# C7XV_RSWS_BS_LIMITER11_REGS register map
Vendor: Texas Instruments
Peripheral module from a debugger description file (folder J722S).
Registers are 32-bit, read-only, reset 0x0 unless marked. A register's access mark holds for its fields unless they carry their own. Offsets are as the file gives them; lines under a group give offsets from that group; [hi:lo] are bit positions; {n}, {i} and the like mark numbered series; 'fields as' and 'values as' point back to an identical list; <NAME> marks a mode.

## C7XV_RSWS_BS_LIMITER11_REGS
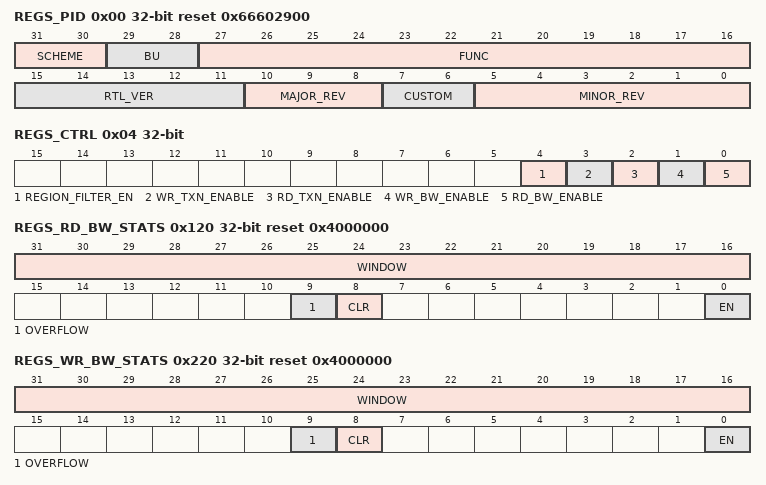
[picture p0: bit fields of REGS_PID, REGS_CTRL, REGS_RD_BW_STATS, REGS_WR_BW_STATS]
0x00 REGS_PID reset 0x66602900 — This is the standard TI peripheral ID register that exists at address 0 in the peripheral space
  [31:30] SCHEME — PID scheme
  [29:28] BU — PID bu identifier
  [27:16] FUNC — PID function identifier
  [15:11] RTL_VER — PID RTL version number
  [10:8] MAJOR_REV — PID Major revision number
  [7:6] CUSTOM — PID custom
  [5:0] MINOR_REV — PID Minor revision number
0x04 REGS_CTRL rw — This register controls the overall behavior of the rate limiter module
  [4] REGION_FILTER_EN — Enable the region filter, which will only apply the bandwith and transaction limits to the configured address regions
  [3] WR_TXN_ENABLE — Enable limiting maximum outstanding write transactions
  [2] RD_TXN_ENABLE — Enable limiting maximum outstanding read transactions
  [1] WR_BW_ENABLE — Enable write bandwidth limiting
  [0] RD_BW_ENABLE — Enable read bandwidth limiting
0x100 REGS_RD_BW_CIR rw — Read Bandwidth Committed Information Rate
  [31:0] CIR — Committed Information Rate
0x104 REGS_RD_BW_PIR rw — Read Bandwidth Peak Information Rate
  [31:0] PIR — Peak Information Rate
0x108 REGS_RD_BW_BURST_OFFSET rw — Read Bandwidth Burst Offset
  [15:0] OFFSET — Burst Offset - the number of bytes before the Committed Information Rate is applied at startup or after a period of inactivity. Peak Information Rate will still apply
0x10C REGS_RD_BW_INFO — Read Bandwidth State machine information. Primarly for verification purposes
  [1:0] COLOR — Read Bandwidth three-color marker output from rategen submodule
0x120 REGS_RD_BW_STATS access per field reset 0x4000000 — Read Bandwidth Statistics Control Register
  [31:16] WINDOW rw — Statistics window size. This cannot be set to 0. If 16'd0 is written, it will be set to the reset value of 16'd1024
  [9] OVERFLOW ro — Statistics overflow error
  [8] CLR wo — Clear statistics data. Resets statistics counters at 0
  [0] EN rw — Enable read bandwidth statistics
0x124 REGS_RD_BW_STATS_THRSHLD rw — A statistics threshold separate from the CIR and PIR
  [31:0] THRESHOLD — Read bandwidth stats threshold in bytes. Note that this is total bytes, unlike CIR and PIR. CIR and PIR are based on a rolling window, and the statistics threshold is based on a fixed window. This will still take into account DDR bytes used, so can be compared to CIR and PIR directly if the bandwidths are converted via the equations for CIR and PIR. The threshold bandwidth is programmed here as bytes per window
0x128 REGS_RD_BW_WINDOWS_CNT — Read Bandwidth Statistics - Window Count
  [31:0] VAL — Read bandwidth window count - the number of windows elapsed since statistics collection began
0x12C REGS_RD_BW_CIR_CNT — Read Bandwidth Statistics - CIR Count
  [31:0] VAL — The total number of statistics windows in which Read Commit Information Rate occurred. Note that if PIR is set to a lower value than CIR or if the burst offset feature is used, this will also count times that PIR is reached.
0x130 REGS_RD_BW_PIR_CNT — Read Bandwidth Statistics - PIR Count
  [31:0] VAL — The total number of statistics windows in which Read Peak Information Rate occurred
0x134 REGS_RD_BW_THRSHLD_CNT — Read Bandwidth Statistics - Threshold Count
  [31:0] VAL — The total number of statistics windows in which Read bytes transferred exceeded the statistics threshold
0x138 REGS_RD_BYTES_MAX — The maximum number of bytes seen in a single statitsics window. This can be compared with the window size to calculate the maximum bandwidth seen
  [31:0] VAL — Max number of bytes in a single window. This number accounts for DDR bandwidth consumed, not simply the accumulation of the packet bytecnt values across a window. The max bandwidth calculation is the total bytes value in this MMR divided by the windows size in RD_BW_STATS.window and multiplied with the interface frequency: RD_BYTES_MAX * FREQ / RD_BW_STATS.window
0x200 REGS_WR_BW_CIR rw — Write Bandwidth Committed Information Rate
  [31:0] CIR — Committed Information Rate
0x204 REGS_WR_BW_PIR rw — Write Bandwidth Peak Information Rate
  [31:0] PIR — Peak Information Rate
0x208 REGS_WR_BW_BURST_OFFSET rw — Write Bandwidth Burst Offset
  fields as REGS_RD_BW_BURST_OFFSET
0x20C REGS_WR_BW_INFO — Write Bandwidth State machine information. Primarly for verification purposes
  [1:0] COLOR — Write Bandwidth three-color marker output from rategen submodule
0x220 REGS_WR_BW_STATS access per field reset 0x4000000 — Write Bandwidth Statistics Control Register
  [31:16] WINDOW rw — Statistics window size. This cannot be set to 0. If 16'd0 is written, it will be set to the reset value of 16'd1024
  [9] OVERFLOW ro — Statistics overflow error
  [8] CLR wo — Clear statistics data. Resets statistics counters at 0
  [0] EN rw — Enable write bandwidth statistics
0x224 REGS_WR_BW_STATS_THRSHLD rw — A statistics threshold separate from the CIR and PIR
  [31:0] THRESHOLD — Write bandwidth stats threshold in bytes. Note that this is total bytes, unlike CIR and PIR. CIR and PIR are based on a rolling window, and the statistics threshold is based on a fixed window. This will still take into account DDR bytes used, so can be compared to CIR and PIR directly if the bandwidths are converted via the equations for CIR and PIR. The threshold bandwidth is programmed here as bytes per window
0x228 REGS_WR_BW_WINDOWS_CNT — Write Bandwidth Statistics - Window Count
  [31:0] VAL — Write bandwidth window count - the number of windows elapsed since statistics collection began
0x22C REGS_WR_BW_CIR_CNT — Write Bandwidth Statistics - CIR Count
  [31:0] VAL — The total number of statistics windows in which Write Commit Information Rate occurred. Note that if PIR is set to a lower value than CIR or if the burst offset feature is used, this will also count times that PIR is reached.
0x230 REGS_WR_BW_PIR_CNT — Write Bandwidth Statistics - PIR Count
  [31:0] VAL — The total number of statistics windows in which Write Peak Information Rate occurred
0x234 REGS_WR_BW_THRSHLD_CNT — Write Bandwidth Statistics - Threshold Count
  [31:0] VAL — The total number of statistics windows in which Write bytes transferred exceeded the statistics threshold
0x238 REGS_WR_BYTES_MAX — The maximum number of bytes seen in a single statitsics window. This can be compared with the window size to calculate the maximum bandwidth seen
  [31:0] VAL — Max number of bytes in a single window. This number accounts for DDR bandwidth consumed, not simply the accumulation of the packet bytecnt values across a window. The max bandwidth calculation is the total bytes value in this MMR divided by the windows size in WR_BW_STATS.window and multiplied with the interface frequency: WR_BYTES_MAX * FREQ / WR_BW_STATS.window
0x300 REGS_RD_TXN rw reset 0x40 — The maximum number of outstanding read transactions the rate limiter will allow
  [15:0] LIMIT — The maximum number of outstanding read transactions allowed. NOTE: This cannot be programmed to a zero. If a zero is written, it will default to the reset value of 16'd64, as a limit of zero outstanding transactions would hang the interface.
0x30C REGS_RD_TXN_INFO — Read Transaction State machine information. Primarly for verification purposes
  [6:0] OCC — Read transaction scoreboard occupancy
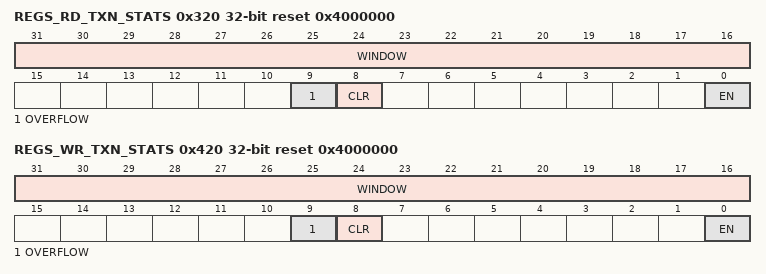
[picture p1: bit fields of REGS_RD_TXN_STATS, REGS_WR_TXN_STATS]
0x320 REGS_RD_TXN_STATS access per field reset 0x4000000 — Read Transaction Stats Control Register
  [31:16] WINDOW rw — Statistics window size. This cannot be set to 0. If 16'd0 is written, it will be set to the reset value of 16'd1024
  [9] OVERFLOW ro — Statistics overflow error
  [8] CLR wo — Clear statistics data. Resets statistics counters at 0
  [0] EN rw — Enable read transaction statistics
0x324 REGS_RD_TXN_STATS_THRSHLD rw — A statistics threshold separate from the read transaction limit
  [15:0] THRESHOLD — Read transaction statistics threshold. The threshold can be set to any value, though it will saturate at the outstanding transaction limit if it is set to a value greater than the programmed outstanding read transaction limit
0x328 REGS_RD_TXN_WINDOWS_CNT — Read Transaction Statistics - Window Count
  [31:0] VAL — Read transaction window count - the number of windows elapsed since statistics collection began
0x32C REGS_RD_TXN_LMT_CNT — Read Transaction Statistics - number of windows in which the outstanding transaction limit was reached
  [31:0] VAL — The number of statistics windows in which the outstanding read transaction limit was reached
0x330 REGS_RD_TXN_THRSHLD_CNT — Read Transaction Statistics - number of windows in which the statistics threshold was reached
  [31:0] VAL — The number of statistics windows in which the number of outstanding read transactions was greater than or equal to the threshold in RD_TXN_STATS_THRSHLD
0x334 REGS_RD_TXN_LIMIT_TOTAL — Read Transaction Statistics - Cycles at Outstanding Read Transactions Limit
  [31:0] VAL — The total number of cycles with the read transactions outstanding at the programmed limit since statistics collection began
0x338 REGS_RD_TXN_THRSHLD_TOTAL — Read Transaction Statistics - Cycles at the Statistics Threshold
  [31:0] VAL — The total number of cycles with read transactions outstanding greater than or equal to the statistics threshold in RD_TXN_STATS_THRSHLD since statistics collection began
0x33C REGS_RD_TXN_MAX — Read Transaction Statistics - Max Observed Outstanding Read Transactions
  [15:0] VAL — The maximum outstanding read transactions at any point in time, regardless of the programmed limit
0x400 REGS_WR_TXN rw reset 0x40 — The maximum number of outstanding write transactions the rate limiter will allow
  [15:0] LIMIT — The maximum number of outstanding write transactions allowed. NOTE: This cannot be programmed to a zero. If a zero is written, it will default to the reset value of 16'd64, as a limit of zero outstanding transactions would hang the interface.
0x40C REGS_WR_TXN_INFO — Write Transaction State machine information. Primarly for verification purposes
  [6:0] OCC — Write transaction scoreboard occupancy
0x420 REGS_WR_TXN_STATS access per field reset 0x4000000 — Write Transaction Stats Control Register
  [31:16] WINDOW rw — Statistics window size. This cannot be set to 0. If 16'd0 is written, it will be set to the reset value of 16'd1024
  [9] OVERFLOW ro — Statistics overflow error
  [8] CLR wo — Clear statistics data. Resets statistics counters at 0
  [0] EN rw — Enable write transaction statistics
0x424 REGS_WR_TXN_STATS_THRSHLD rw — A statistics threshold separate from the write transaction limit
  [15:0] THRESHOLD — Write transaction statistics threshold. The threshold can be set to any value, though it will saturate at the outstanding transaction limit if it is set to a value greater than the programmed outstanding write transaction limit
0x428 REGS_WR_TXN_WINDOWS_CNT — Write Transaction Statistics - Window Count
  [31:0] VAL — Write transaction window count - the number of windows elapsed since statistics collection began
0x42C REGS_WR_TXN_LMT_CNT — Write Transaction Statistics - number of windows in which the outstanding transaction limit was reached
  [31:0] VAL — The number of statistics windows in which the outstanding write transaction limit was reached
0x430 REGS_WR_TXN_THRSHLD_CNT — Write Transaction Statistics - number of windows in which the statistics threshold was reached
  [31:0] VAL — The number of statistics windows in which the number of outstanding write transactions was greater than or equal to the threshold in WR_TXN_STATS_THRSHLD
0x434 REGS_WR_TXN_LIMIT_TOTAL — Write Transaction Statistics - Cycles at Outstanding Write Transactions Limit
  [31:0] VAL — The total number of cycles with the write transactions outstanding at the programmed limit since statistics collection began
0x438 REGS_WR_TXN_THRSHLD_TOTAL — Write Transaction Statistics - Cycles at the Statistics Threshold
  [31:0] VAL — The total number of cycles with write transactions outstanding greater than or equal to the statistics threshold in WR_TXN_STATS_THRSHLD since statistics collection began
0x43C REGS_WR_TXN_MAX — Write Transaction Statistics - Max Observed Outstanding Write Transactions
  [15:0] VAL — The maximum outstanding write transactions at any point in time, regardless of the programmed limit
